/*LIN_GUI_custom: BIC */
/* Mahle Electronics */
/* All rights reserved */
/* Description: LIN Description file */
/* Network: HVAC */
/* Release: 2020 */
/* Engineer: C.Sevilla / Brett Bowman */
/* Creation Date: 2020-01-23 */
/* Status: RELEASED */
/* XDIS-Database: MBC-Database */

LIN_description_file;
LIN_protocol_version = "2.1";
LIN_language_version = "2.1";
LIN_speed = 19.2 kbps;
Channel_name = "HVAC";

Nodes {
  Master: HVAC, 5 ms, 0.17 ms ;
  Slaves: EAC ;
}

Signals {
  CompSpd_Target: 8, 255, HVAC, EAC ;
  Comp_On_Rq: 2, 3, HVAC, EAC ;
  Comp_Fault_Clear_Rq: 2, 3, HVAC, EAC ;
  Comp_HvInterlock_Rq: 2, 3, HVAC, EAC ;
  Comp_HvDischarge_Rq: 2, 3, HVAC, EAC ;
  CompSpd_Est: 8, 255, EAC, HVAC ;
  EAC_HV_InputCurr: 8, 255, EAC, HVAC ;
  EAC_HV_Volt: 8, 255, EAC, HVAC ;
  EAC_InvrtTemp: 8, 255, EAC, HVAC ;
  EAC_InvrtPhaseCurr: 8, 255, EAC, HVAC ;
  EAC_Sp_BrdTemp_Lmt: 1, 1, EAC, HVAC ;
  EAC_Sp_CurrLmt: 1, 1, EAC, HVAC ;
  EAC_Sp_HVVolt_Flt: 1, 1, EAC, HVAC ;
  EAC_Sp_Temp_Excess: 1, 1, EAC, HVAC ;
  EAC_Sp_Comm_Flt: 1, 1, EAC, HVAC ;
  EAC_Sp_InvrtPwrSup_Flt: 1, 1, EAC, HVAC ;
  EAC_Off_Sens_Flt: 1, 1, EAC, HVAC ;
  EAC_Off_ShrtCurr: 1, 1, EAC, HVAC ;
  EAC_Off_Stall: 1, 1, EAC, HVAC ;
  EAC_RsErr: 1, 1, EAC, HVAC ;
  Comp_HvInterlock_Stat: 3, 7, EAC, HVAC ;
  Comp_Oprtn_Stat: 3, 7, EAC, HVAC ;
}

Frames {
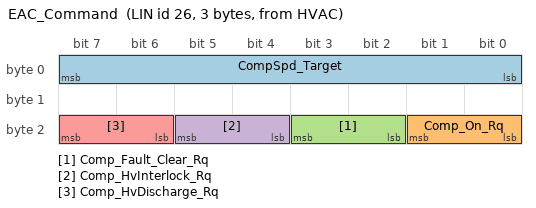
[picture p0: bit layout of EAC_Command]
  EAC_Command: 26, HVAC, 3 {
    CompSpd_Target, 0 ;
    Comp_On_Rq, 16 ;
    Comp_Fault_Clear_Rq, 18 ;
    Comp_HvInterlock_Rq, 20 ;
    Comp_HvDischarge_Rq, 22 ;
  }
  EAC_Status: 27, EAC, 8 {
    CompSpd_Est, 0 ;
    EAC_HV_InputCurr, 16 ;
    EAC_HV_Volt, 24 ;
    EAC_InvrtTemp, 32 ;
    EAC_InvrtPhaseCurr, 40 ;
    EAC_Sp_BrdTemp_Lmt, 48 ;
    EAC_Sp_CurrLmt, 49 ;
    EAC_Sp_HVVolt_Flt, 50 ;
    EAC_Sp_Temp_Excess, 51 ;
    EAC_Sp_Comm_Flt, 52 ;
    EAC_Sp_InvrtPwrSup_Flt, 53 ;
    EAC_Off_Sens_Flt, 54 ;
    EAC_Off_ShrtCurr, 55 ;
    EAC_Off_Stall, 56 ;
    EAC_RsErr, 57 ;
    Comp_HvInterlock_Stat, 58 ;
    Comp_Oprtn_Stat, 61 ;
  }
}

Node_attributes {
  EAC{
    LIN_protocol = "2.1" ;
    configured_NAD = 0x5C ;
    initial_NAD = 0x5C ;
    product_id = 0x91, 0x500, 0 ;
    response_error = EAC_RsErr ;
    P2_min = 50 ms ;
    ST_min = 0 ms ;
    N_As_timeout = 1000 ms ;
    N_Cr_timeout = 1000 ms ;
    configurable_frames {
      EAC_Status ;
      EAC_Command ;
    }
  }
}

Schedule_tables {
 sch_diag {
    MasterReq delay 50 ms ;
    SlaveResp delay 50 ms ;
  }
 sch_normal {
    EAC_Command delay 100 ms ;
    EAC_Status delay 100 ms ;
  }
}

Signal_encoding_types {
  c8_rpm_0_12700_50 {
    physical_value, 0, 254, 50, 0, "rpm" ;
    logical_value, 255, "SNA" ;
  }
  c02_Comp_Rq {
    logical_value, 0, "OFF" ;
    logical_value, 1, "ON" ;
    logical_value, 2, "NDEF2" ;
    logical_value, 3, "SNA" ;
  }
  c02_Reset_Rq {
    logical_value, 0, "NO_RESET" ;
    logical_value, 1, "RESET" ;
    logical_value, 2, "NDEF2" ;
    logical_value, 3, "SNA" ;
  }
  c08_V_0_1270_5 {
    physical_value, 0, 254, 5, 0, "V" ;
    logical_value, 255, "SNA" ;
  }
  c08_degC_m50_204_1 {
    physical_value, 0, 254, 1, -50, "Celsius" ;
    logical_value, 255, "SNA" ;
  }
  c08_A_0_127_0_5 {
    physical_value, 0, 254, 0.5, 0, "A" ;
    logical_value, 255, "SNA" ;
  }
  c02_NoErr_Err_Stat {
    logical_value, 0, "NO_ERROR" ;
    logical_value, 1, "ERROR" ;
  }
  c03_HvInterlock_Stat {
    logical_value, 0, "OFF" ;
    logical_value, 1, "CLOSED" ;
    logical_value, 2, "OPEN" ;
    logical_value, 3, "OVERCURRENT" ;
    logical_value, 4, "HW_ERROR" ;
    logical_value, 7, "SNA" ;
  }
  c03_Comp_Stat {
    logical_value, 0, "COMP_OFF" ;
    logical_value, 1, "COMP_ON" ;
    logical_value, 2, "COMP_STOPP" ;
    logical_value, 3, "COMP_DIRECTPWM" ;
    logical_value, 4, "COMP_ON_DEGRADED" ;
    logical_value, 7, "SNA" ;
  }
}

Signal_representation {
  c02_Comp_Rq: Comp_On_Rq, Comp_HvInterlock_Rq, Comp_HvDischarge_Rq ;
  c02_NoErr_Err_Stat: EAC_Sp_BrdTemp_Lmt, EAC_Sp_CurrLmt, EAC_Sp_HVVolt_Flt, EAC_Sp_Temp_Excess, EAC_Sp_Comm_Flt, EAC_Sp_InvrtPwrSup_Flt, EAC_Off_Sens_Flt, EAC_Off_ShrtCurr, EAC_Off_Stall, EAC_RsErr ;
  c02_Reset_Rq: Comp_Fault_Clear_Rq ;
  c03_Comp_Stat: Comp_Oprtn_Stat ;
  c03_HvInterlock_Stat: Comp_HvInterlock_Stat ;
  c08_A_0_127_0_5: EAC_HV_InputCurr, EAC_InvrtPhaseCurr ;
  c08_V_0_1270_5: EAC_HV_Volt ;
  c08_degC_m50_204_1: EAC_InvrtTemp ;
  c8_rpm_0_12700_50: CompSpd_Target, CompSpd_Est ;
}
